[part 1 of 3: package /STELLANTIS/EPT/ASWCs]
AUTOSAR XML (schema 4-2-2)
package /STELLANTIS/EPT/ASWCs
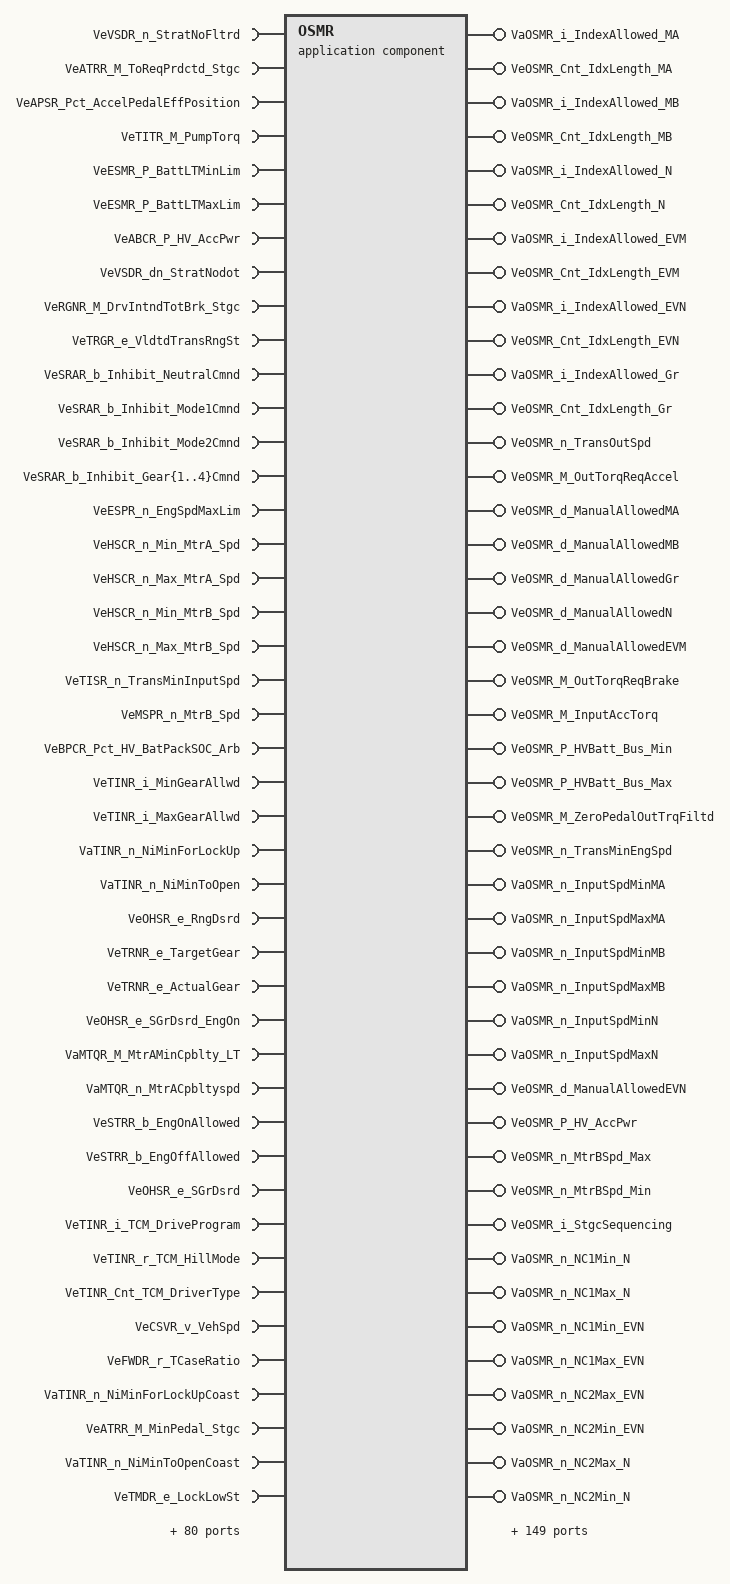
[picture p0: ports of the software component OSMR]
  application sw component type OSMR
    127 x require port:
      VeVSDR_n_StratNoFltrd: nonqueued-receiver-com-spec{data-element=Value, init-value=0}, required-interface=VeVSDR_n_StratNoFltrd
      VeATRR_M_ToReqPrdctd_Stgc: nonqueued-receiver-com-spec{data-element=Value, init-value=0}, required-interface=VeATRR_M_ToReqPrdctd_Stgc
      VeAPSR_Pct_AccelPedalEffPosition: nonqueued-receiver-com-spec{data-element=Value, init-value=0}, required-interface=VeAPSR_Pct_AccelPedalEffPosition
      VeTITR_M_PumpTorq: nonqueued-receiver-com-spec{data-element=Value, init-value=0}, required-interface=VeTITR_M_PumpTorq
      VeESMR_P_BattLTMinLim: nonqueued-receiver-com-spec{data-element=Value, init-value=0}, required-interface=VeESMR_P_BattLTMinLim
      VeESMR_P_BattLTMaxLim: nonqueued-receiver-com-spec{data-element=Value, init-value=0}, required-interface=VeESMR_P_BattLTMaxLim
      VeABCR_P_HV_AccPwr: nonqueued-receiver-com-spec{data-element=Value, init-value=0}, required-interface=VeABCR_P_HV_AccPwr
      VeVSDR_dn_StratNodot: nonqueued-receiver-com-spec{data-element=Value, init-value=0}, required-interface=VeVSDR_dn_StratNodot
      VeRGNR_M_DrvIntndTotBrk_Stgc: nonqueued-receiver-com-spec{data-element=Value, init-value=0}, required-interface=VeRGNR_M_DrvIntndTotBrk_Stgc
      VeTRGR_e_VldtdTransRngSt: nonqueued-receiver-com-spec{data-element=Value, init-value=CeTRGR_e_NoSelectionAvailable}, required-interface=VeTRGR_e_VldtdTransRngSt
      VeSRAR_b_Inhibit_NeutralCmnd: nonqueued-receiver-com-spec{data-element=Value, init-value=0}, required-interface=VeSRAR_b_Inhibit_NeutralCmnd
      VeSRAR_b_Inhibit_Mode1Cmnd: nonqueued-receiver-com-spec{data-element=Value, init-value=0}, required-interface=VeSRAR_b_Inhibit_Mode1Cmnd
      VeSRAR_b_Inhibit_Mode2Cmnd: nonqueued-receiver-com-spec{data-element=Value, init-value=0}, required-interface=VeSRAR_b_Inhibit_Mode2Cmnd
      VeSRAR_b_Inhibit_Gear{1..4}Cmnd: nonqueued-receiver-com-spec{data-element=Value, init-value=0}, required-interface=VeSRAR_b_Inhibit_Gear{1..4}Cmnd
      VeESPR_n_EngSpdMaxLim: nonqueued-receiver-com-spec{data-element=Value, init-value=0}, required-interface=VeESPR_n_EngSpdMaxLim
      VeHSCR_n_Min_MtrA_Spd: nonqueued-receiver-com-spec{data-element=Value, init-value=0}, required-interface=VeHSCR_n_Min_MtrA_Spd
      VeHSCR_n_Max_MtrA_Spd: nonqueued-receiver-com-spec{data-element=Value, init-value=0}, required-interface=VeHSCR_n_Max_MtrA_Spd
      VeHSCR_n_Min_MtrB_Spd: nonqueued-receiver-com-spec{data-element=Value, init-value=0}, required-interface=VeHSCR_n_Min_MtrB_Spd
      VeHSCR_n_Max_MtrB_Spd: nonqueued-receiver-com-spec{data-element=Value, init-value=0}, required-interface=VeHSCR_n_Max_MtrB_Spd
      VeTISR_n_TransMinInputSpd: nonqueued-receiver-com-spec{data-element=Value, init-value=0}, required-interface=VeTISR_n_TransMinInputSpd
      VeMSPR_n_MtrB_Spd: variation-point={short-label=vpVeMSPR_n_MtrB_Spd, sw-syscond=1}, nonqueued-receiver-com-spec{data-element=Value, init-value=0}, required-interface=VeMSPR_n_MtrB_Spd
      VeBPCR_Pct_HV_BatPackSOC_Arb: nonqueued-receiver-com-spec{data-element=Value, init-value=0}, required-interface=VeBPCR_Pct_HV_BatPackSOC_Arb
      VeTINR_i_MinGearAllwd: nonqueued-receiver-com-spec{data-element=Value, init-value=0}, required-interface=VeTINR_i_MinGearAllwd
      VeTINR_i_MaxGearAllwd: nonqueued-receiver-com-spec{data-element=Value, init-value=0}, required-interface=VeTINR_i_MaxGearAllwd
      VaTINR_n_NiMinForLockUp: nonqueued-receiver-com-spec{data-element=Value, init-value=9 x 0}, required-interface=VaTINR_n_NiMinForLockUp
      VaTINR_n_NiMinToOpen: nonqueued-receiver-com-spec{data-element=Value, init-value=9 x 0}, required-interface=VaTINR_n_NiMinToOpen
      VeOHSR_e_RngDsrd: nonqueued-receiver-com-spec{data-element=Value, init-value=CeOHSR_e_RngSel_N}, required-interface=VeOHSR_e_RngDsrd
      VeTRNR_e_TargetGear: nonqueued-receiver-com-spec{data-element=Value, init-value=CeTRNR_e_Neutral}, required-interface=VeTRNR_e_TargetGear
      VeTRNR_e_ActualGear: nonqueued-receiver-com-spec{data-element=Value, init-value=CeTRNR_e_Neutral}, required-interface=VeTRNR_e_ActualGear
      VeOHSR_e_SGrDsrd_EngOn: nonqueued-receiver-com-spec{data-element=Value, init-value=CeOHSR_e_SG_Reverse}, required-interface=VeOHSR_e_SGrDsrd_EngOn
      VaMTQR_M_MtrAMinCpblty_LT: nonqueued-receiver-com-spec{data-element=Value, init-value=16 x 0}, required-interface=VaMTQR_M_MtrAMinCpblty_LT
      VaMTQR_n_MtrACpbltyspd: nonqueued-receiver-com-spec{data-element=Value, init-value=16 x 0}, required-interface=VaMTQR_n_MtrACpbltyspd
      VeSTRR_b_EngOnAllowed: nonqueued-receiver-com-spec{data-element=Value, init-value=0}, required-interface=VeSTRR_b_EngOnAllowed
      VeSTRR_b_EngOffAllowed: nonqueued-receiver-com-spec{data-element=Value, init-value=0}, required-interface=VeSTRR_b_EngOffAllowed
      VeOHSR_e_SGrDsrd: nonqueued-receiver-com-spec{data-element=Value, init-value=CeOHSR_e_SG_Reverse}, required-interface=VeOHSR_e_SGrDsrd
      VeTINR_i_TCM_DriveProgram: nonqueued-receiver-com-spec{data-element=Value, init-value=0}, required-interface=VeTINR_i_TCM_DriveProgram
      VeTINR_r_TCM_HillMode: nonqueued-receiver-com-spec{data-element=Value, init-value=0}, required-interface=VeTINR_r_TCM_HillMode
      VeTINR_Cnt_TCM_DriverType: nonqueued-receiver-com-spec{data-element=Value, init-value=0}, required-interface=VeTINR_Cnt_TCM_DriverType
      VeCSVR_v_VehSpd: nonqueued-receiver-com-spec{data-element=Value, init-value=0}, required-interface=VeCSVR_v_VehSpd
      VeFWDR_r_TCaseRatio: nonqueued-receiver-com-spec{data-element=Value, init-value=0}, required-interface=VeFWDR_r_TCaseRatio
      VaTINR_n_NiMinForLockUpCoast: nonqueued-receiver-com-spec{data-element=Value, init-value=9 x 0}, required-interface=VaTINR_n_NiMinForLockUpCoast
      VeATRR_M_MinPedal_Stgc: nonqueued-receiver-com-spec{data-element=Value, init-value=0}, required-interface=VeATRR_M_MinPedal_Stgc
      VaTINR_n_NiMinToOpenCoast: nonqueued-receiver-com-spec{data-element=Value, init-value=9 x 0}, required-interface=VaTINR_n_NiMinToOpenCoast
      VeTMDR_e_LockLowSt: nonqueued-receiver-com-spec{data-element=Value, init-value=CeTMDR_e_Off}, required-interface=VeTMDR_e_LockLowSt
      VeCSVR_l_WhlRadius: nonqueued-receiver-com-spec{data-element=Value, init-value=0}, required-interface=VeCSVR_l_WhlRadius
      VeCTCR_b_MinCreep_Enable: nonqueued-receiver-com-spec{data-element=Value, init-value=0}, required-interface=VeCTCR_b_MinCreep_Enable
      VeTRGR_b_ManualMode: nonqueued-receiver-com-spec{data-element=Value, init-value=0}, required-interface=VeTRGR_b_ManualMode
      VeEOCR_r_ColdCtrlCostFact_Stgc: nonqueued-receiver-com-spec{data-element=Value, init-value=0}, required-interface=VeEOCR_r_ColdCtrlCostFact_Stgc
      VeFWDR_e_Tcase_Stat: nonqueued-receiver-com-spec{data-element=Value, init-value=CeFWDR_e_ShiftINProg}, required-interface=VeFWDR_e_Tcase_Stat
      VeTMDR_i_TrueTrrnMd: nonqueued-receiver-com-spec{data-element=Value, init-value=0}, required-interface=VeTMDR_i_TrueTrrnMd
      VeHSER_e_HRSR_State: variation-point={short-label=vpVeHSER_e_HRSR_State, sw-syscond=1}, nonqueued-receiver-com-spec{data-element=Value, init-value=CeHSER_e_Neut_State}, required-interface=VeHSER_e_HRSR_State
      VeTRNR_e_TCM_ActiveHybridGear: nonqueued-receiver-com-spec{data-element=Value, init-value=CeTRNR_e_Neutral}, required-interface=VeTRNR_e_TCM_ActiveHybridGear
      VeTRNR_e_TCM_ActiveXNGear: nonqueued-receiver-com-spec{data-element=Value, init-value=CeTRNR_e_Neutral}, required-interface=VeTRNR_e_TCM_ActiveXNGear
      VeTRNR_e_TCM_ActiveEVGear: nonqueued-receiver-com-spec{data-element=Value, init-value=CeTRNR_e_Neutral}, required-interface=VeTRNR_e_TCM_ActiveEVGear
      VeFWDR_r_Axle_Ratio: nonqueued-receiver-com-spec{data-element=Value, init-value=0}, required-interface=VeFWDR_r_Axle_Ratio
      VaETQR_M_EngCapabilityMax: nonqueued-receiver-com-spec{data-element=Value, init-value=16 x 0}, required-interface=VaETQR_M_EngCapabilityMax
      VaETQR_n_EngCapability: nonqueued-receiver-com-spec{data-element=Value, init-value=16 x 0}, required-interface=VaETQR_n_EngCapability
      VeTINR_t_TCM_TimeToSpeedChange: nonqueued-receiver-com-spec{data-element=Value, init-value=0}, required-interface=VeTINR_t_TCM_TimeToSpeedChange
      VeHSCR_n_Min_MtrC_Spd: nonqueued-receiver-com-spec{data-element=Value, init-value=0}, required-interface=VeHSCR_n_Min_MtrC_Spd
      VeHSCR_n_Max_MtrC_Spd: nonqueued-receiver-com-spec{data-element=Value, init-value=0}, required-interface=VeHSCR_n_Max_MtrC_Spd
      VeADCR_e_WEDCmndArb: variation-point={short-label=vpVeADCR_e_WEDCmndArb, sw-syscond=1}, nonqueued-receiver-com-spec{data-element=Value, init-value=CeADCR_e_ReqOpt}, required-interface=VeADCR_e_WEDCmndArb
      VeINVR_e_MtrA_InvrtrSt: nonqueued-receiver-com-spec{data-element=Value, init-value=CeINVR_e_NormalPowerStageOff}, required-interface=VeINVR_e_MtrA_InvrtrSt
      VeBPCR_e_HV_BatCntctrStat: nonqueued-receiver-com-spec{data-element=Value, init-value=CeHVTR_e_Open}, required-interface=VeBPCR_e_HV_BatCntctrStat
      VeENGR_b_PnLimitActvFlg: nonqueued-receiver-com-spec{data-element=Value, init-value=0}, required-interface=VeENGR_b_PnLimitActvFlg
      VeESMR_P_BoostCnvrtr_LT_ChrgPwrLmt: nonqueued-receiver-com-spec{data-element=Value, init-value=0}, required-interface=VeESMR_P_BoostCnvrtr_LT_ChrgPwrLmt
      VeESMR_P_BoostCnvrtr_LT_DschrgPwrLmt: nonqueued-receiver-com-spec{data-element=Value, init-value=0}, required-interface=VeESMR_P_BoostCnvrtr_LT_DschrgPwrLmt
      VeTIMR_e_RaceOptions_Sts: nonqueued-receiver-com-spec{data-element=Value, init-value=CeTIMR_e_NoOptionSelected}, required-interface=VeTIMR_e_RaceOptions_Sts
      VeDMDR_i_DrvMdArbIdx: nonqueued-receiver-com-spec{data-element=Value, init-value=0}, required-interface=VeDMDR_i_DrvMdArbIdx
      VaMTQR_n_MtrBCpbltyspd: nonqueued-receiver-com-spec{data-element=Value, init-value=16 x 0}, required-interface=VaMTQR_n_MtrBCpbltyspd
      VaMTQR_n_MtrCCpbltyspd: nonqueued-receiver-com-spec{data-element=Value, init-value=16 x 0}, required-interface=VaMTQR_n_MtrCCpbltyspd
      VaMTQR_M_MtrAMaxCpblty_LT: nonqueued-receiver-com-spec{data-element=Value, init-value=16 x 0}, required-interface=VaMTQR_M_MtrAMaxCpblty_LT
      VaMTQR_M_MtrBMaxCpblty_LT: nonqueued-receiver-com-spec{data-element=Value, init-value=16 x 0}, required-interface=VaMTQR_M_MtrBMaxCpblty_LT
      VaMTQR_M_MtrCMaxCpblty_LT: nonqueued-receiver-com-spec{data-element=Value, init-value=16 x 0}, required-interface=VaMTQR_M_MtrCMaxCpblty_LT
      VeADCR_i_WEDCmndArbPrioLvl: variation-point={short-label=vpVeADCR_i_WEDCmndArbPrioLvl, sw-syscond=1}, nonqueued-receiver-com-spec{data-element=Value, init-value=0}, required-interface=VeADCR_i_WEDCmndArbPrioLvl
      VeEBMR_e_eBoostStatus: variation-point={short-label=vpVeEBMR_e_eBoostStatus, sw-syscond=1}, nonqueued-receiver-com-spec{data-element=Value, init-value=CeEBMR_e_eBoostOFF}, required-interface=VeEBMR_e_eBoostStatus
      VeENGR_b_OilDil_EngMinPwrEnbl: nonqueued-receiver-com-spec{data-element=Value, init-value=0}, required-interface=VeENGR_b_OilDil_EngMinPwrEnbl
      VaETQR_M_EngCapabilityMinOff: nonqueued-receiver-com-spec{data-element=Value, init-value=16 x 0}, required-interface=VaETQR_M_EngCapabilityMinOff
      VeSRAR_b_limitInputTrq: nonqueued-receiver-com-spec{data-element=Value, init-value=0}, required-interface=VeSRAR_b_limitInputTrq
      VeSTRR_e_HybStrtrSt: nonqueued-receiver-com-spec{data-element=Value, init-value=CeSTRR_e_KeyOffSt}, required-interface=VeSTRR_e_HybStrtrSt
      VeOHSR_b_EngDsrd: nonqueued-receiver-com-spec{data-element=Value, init-value=0}, required-interface=VeOHSR_b_EngDsrd
      VeWTAR_M_FrntAxlMaxRq: nonqueued-receiver-com-spec{data-element=Value, init-value=0}, required-interface=VeWTAR_M_FrntAxlMaxRq
      VeWTAR_M_FrntAxlMinRq: nonqueued-receiver-com-spec{data-element=Value, init-value=0}, required-interface=VeWTAR_M_FrntAxlMinRq
      VeWTAR_M_RrAxlMaxRq: nonqueued-receiver-com-spec{data-element=Value, init-value=0}, required-interface=VeWTAR_M_RrAxlMaxRq
      VeWTAR_M_RrAxlMinRq: nonqueued-receiver-com-spec{data-element=Value, init-value=0}, required-interface=VeWTAR_M_RrAxlMinRq
      VeWTAR_r_PRNDL_Coeff: nonqueued-receiver-com-spec{data-element=Value, init-value=0}, required-interface=VeWTAR_r_PRNDL_Coeff
      VaOMNR_M_PrevToFOpt_N: variation-point={short-label=vpVaOMNR_M_PrevToFOpt_N, sw-syscond=1}, nonqueued-receiver-com-spec{data-element=Value, init-value=9 x 0}, required-interface=VaOMNR_M_PrevToFOpt_N
      VaOMAR_M_PrevToFOpt_MA: nonqueued-receiver-com-spec{data-element=Value, init-value=9 x 0}, required-interface=VaOMAR_M_PrevToFOpt_MA
      VaOMBR_M_PrevToFOpt_MB: nonqueued-receiver-com-spec{data-element=Value, init-value=9 x 0}, required-interface=VaOMBR_M_PrevToFOpt_MB
      VaOGRR_M_PrevToFOpt_GB: nonqueued-receiver-com-spec{data-element=Value, init-value=9 x 0}, required-interface=VaOGRR_M_PrevToFOpt_GB
      VaOEVR_M_PrevToFOpt_EVM: nonqueued-receiver-com-spec{data-element=Value, init-value=9 x 0}, required-interface=VaOEVR_M_PrevToFOpt_EVM
      VaOEVR_M_PrevToFOpt_EVN: nonqueued-receiver-com-spec{data-element=Value, init-value=9 x 0}, required-interface=VaOEVR_M_PrevToFOpt_EVN
      VaOMNR_M_PrevToROpt_N: variation-point={short-label=vpVaOMNR_M_PrevToROpt_N, sw-syscond=1}, nonqueued-receiver-com-spec{data-element=Value, init-value=9 x 0}, required-interface=VaOMNR_M_PrevToROpt_N
      VaOMAR_M_PrevToROpt_MA: nonqueued-receiver-com-spec{data-element=Value, init-value=9 x 0}, required-interface=VaOMAR_M_PrevToROpt_MA
      VaOMBR_M_PrevToROpt_MB: nonqueued-receiver-com-spec{data-element=Value, init-value=9 x 0}, required-interface=VaOMBR_M_PrevToROpt_MB
      VaOGRR_M_PrevToROpt_GB: nonqueued-receiver-com-spec{data-element=Value, init-value=9 x 0}, required-interface=VaOGRR_M_PrevToROpt_GB
      VaOEVR_M_PrevToROpt_EVM: nonqueued-receiver-com-spec{data-element=Value, init-value=9 x 0}, required-interface=VaOEVR_M_PrevToROpt_EVM
      VaOEVR_M_PrevToROpt_EVN: nonqueued-receiver-com-spec{data-element=Value, init-value=9 x 0}, required-interface=VaOEVR_M_PrevToROpt_EVN
      VeBACR_r_CostFactSOCNeg_Stgc: nonqueued-receiver-com-spec{data-element=Value, init-value=0}, required-interface=VeBACR_r_CostFactSOCNeg_Stgc
      VeBACR_r_CostFactSOCPos_Stgc: nonqueued-receiver-com-spec{data-element=Value, init-value=0}, required-interface=VeBACR_r_CostFactSOCPos_Stgc
      VeBACR_P_BattPwrShift_Stgc: nonqueued-receiver-com-spec{data-element=Value, init-value=0}, required-interface=VeBACR_P_BattPwrShift_Stgc
      VeEOCR_n_Ni_ColdCtrl: nonqueued-receiver-com-spec{data-element=Value, init-value=0}, required-interface=VeEOCR_n_Ni_ColdCtrl
      VeEOCR_M_Ti_ColdCtrl_Stgc: nonqueued-receiver-com-spec{data-element=Value, init-value=0}, required-interface=VeEOCR_M_Ti_ColdCtrl_Stgc
      VeBACR_P_BattPwrShift_ZeroPdl: nonqueued-receiver-com-spec{data-element=Value, init-value=0}, required-interface=VeBACR_P_BattPwrShift_ZeroPdl
      VeSCCR_b_PerfAWDFlag: variation-point={short-label=vpVeSCCR_b_PerfAWDFlag, sw-syscond=1}, nonqueued-receiver-com-spec{data-element=Value, init-value=0}, required-interface=VeSCCR_b_PerfAWDFlag
      VeSCCR_M_FrntAxlAdhMax: nonqueued-receiver-com-spec{data-element=Value, init-value=0}, required-interface=VeSCCR_M_FrntAxlAdhMax
      VeSCCR_M_FrntAxlAdhMin: nonqueued-receiver-com-spec{data-element=Value, init-value=0}, required-interface=VeSCCR_M_FrntAxlAdhMin
      VeSCCR_M_RrAxlAdhMax: nonqueued-receiver-com-spec{data-element=Value, init-value=0}, required-interface=VeSCCR_M_RrAxlAdhMax
      VeSCCR_M_RrAxlAdhMin: nonqueued-receiver-com-spec{data-element=Value, init-value=0}, required-interface=VeSCCR_M_RrAxlAdhMin
      VeSCCR_M_FrntAxlStrtgcMax_OL: variation-point={short-label=vpVeSCCR_M_FrntAxlStrtgcMax_OL, sw-syscond=1}, nonqueued-receiver-com-spec{data-element=Value, init-value=0}, required-interface=VeSCCR_M_FrntAxlStrtgcMax_OL
      VeSCCR_M_FrntAxlStrtgcMin_OL: variation-point={short-label=vpVeSCCR_M_FrntAxlStrtgcMin_OL, sw-syscond=1}, nonqueued-receiver-com-spec{data-element=Value, init-value=0}, required-interface=VeSCCR_M_FrntAxlStrtgcMin_OL
      VeSCCR_M_RrAxlStrtgcMax_OL: variation-point={short-label=vpVeSCCR_M_RrAxlStrtgcMax_OL, sw-syscond=1}, nonqueued-receiver-com-spec{data-element=Value, init-value=0}, required-interface=VeSCCR_M_RrAxlStrtgcMax_OL
      VeSCCR_M_RrAxlStrtgcMin_OL: variation-point={short-label=vpVeSCCR_M_RrAxlStrtgcMin_OL, sw-syscond=1}, nonqueued-receiver-com-spec{data-element=Value, init-value=0}, required-interface=VeSCCR_M_RrAxlStrtgcMin_OL
      VeADCR_P_PwrRsrv4EngmtRaw: nonqueued-receiver-com-spec{data-element=Value, init-value=0}, required-interface=VeADCR_P_PwrRsrv4EngmtRaw
      VeBCPR_M_BeltCapMaxPrll: nonqueued-receiver-com-spec{data-element=Value, init-value=0}, required-interface=VeBCPR_M_BeltCapMaxPrll
      VeBCPR_M_BeltCapMinPrll: nonqueued-receiver-com-spec{data-element=Value, init-value=0}, required-interface=VeBCPR_M_BeltCapMinPrll
      VeBCPR_M_BeltCapMaxSer_Eff: nonqueued-receiver-com-spec{data-element=Value, init-value=0}, required-interface=VeBCPR_M_BeltCapMaxSer_Eff
      VeBCPR_M_BeltCapMinSer_Eff: nonqueued-receiver-com-spec{data-element=Value, init-value=0}, required-interface=VeBCPR_M_BeltCapMinSer_Eff
      VeINVR_T_MtrA_Temp: nonqueued-receiver-com-spec{data-element=Value, init-value=0}, required-interface=VeINVR_T_MtrA_Temp
      VeINVR_T_MtrA_InvrtrTemp: nonqueued-receiver-com-spec{data-element=Value, init-value=0}, required-interface=VeINVR_T_MtrA_InvrtrTemp
      VeINVR_T_MtrB_Temp: nonqueued-receiver-com-spec{data-element=Value, init-value=0}, required-interface=VeINVR_T_MtrB_Temp
      VeINVR_T_MtrB_InvrtrTemp: nonqueued-receiver-com-spec{data-element=Value, init-value=0}, required-interface=VeINVR_T_MtrB_InvrtrTemp
      VeINVR_T_MtrC_Temp: nonqueued-receiver-com-spec{data-element=Value, init-value=0}, required-interface=VeINVR_T_MtrC_Temp
      VeINVR_T_MtrC_InvrtrTemp: nonqueued-receiver-com-spec{data-element=Value, init-value=0}, required-interface=VeINVR_T_MtrC_InvrtrTemp
      VeBPCR_T_BatModTmp: nonqueued-receiver-com-spec{data-element=Value, init-value=0}, required-interface=VeBPCR_T_BatModTmp
    193 x provide port:
      VaOSMR_i_IndexAllowed_MA: nonqueued-sender-com-spec{data-element=Value, init-value=9 x 0}, provided-interface=VaOSMR_i_IndexAllowed_MA
      VeOSMR_Cnt_IdxLength_MA: nonqueued-sender-com-spec{data-element=Value, init-value=0}, provided-interface=VeOSMR_Cnt_IdxLength_MA
      VaOSMR_i_IndexAllowed_MB: nonqueued-sender-com-spec{data-element=Value, init-value=9 x 0}, provided-interface=VaOSMR_i_IndexAllowed_MB
      VeOSMR_Cnt_IdxLength_MB: nonqueued-sender-com-spec{data-element=Value, init-value=0}, provided-interface=VeOSMR_Cnt_IdxLength_MB
      VaOSMR_i_IndexAllowed_N: nonqueued-sender-com-spec{data-element=Value, init-value=9 x 0}, provided-interface=VaOSMR_i_IndexAllowed_N
      VeOSMR_Cnt_IdxLength_N: nonqueued-sender-com-spec{data-element=Value, init-value=0}, provided-interface=VeOSMR_Cnt_IdxLength_N
      VaOSMR_i_IndexAllowed_EVM: nonqueued-sender-com-spec{data-element=Value, init-value=9 x 0}, provided-interface=VaOSMR_i_IndexAllowed_EVM
      VeOSMR_Cnt_IdxLength_EVM: nonqueued-sender-com-spec{data-element=Value, init-value=0}, provided-interface=VeOSMR_Cnt_IdxLength_EVM
      VaOSMR_i_IndexAllowed_EVN: nonqueued-sender-com-spec{data-element=Value, init-value=9 x 0}, provided-interface=VaOSMR_i_IndexAllowed_EVN
      VeOSMR_Cnt_IdxLength_EVN: nonqueued-sender-com-spec{data-element=Value, init-value=0}, provided-interface=VeOSMR_Cnt_IdxLength_EVN
      VaOSMR_i_IndexAllowed_Gr: nonqueued-sender-com-spec{data-element=Value, init-value=9 x 0}, provided-interface=VaOSMR_i_IndexAllowed_Gr
      VeOSMR_Cnt_IdxLength_Gr: nonqueued-sender-com-spec{data-element=Value, init-value=0}, provided-interface=VeOSMR_Cnt_IdxLength_Gr
      VeOSMR_n_TransOutSpd: nonqueued-sender-com-spec{data-element=Value, init-value=0}, provided-interface=VeOSMR_n_TransOutSpd
      VeOSMR_M_OutTorqReqAccel: nonqueued-sender-com-spec{data-element=Value, init-value=0}, provided-interface=VeOSMR_M_OutTorqReqAccel
      VeOSMR_d_ManualAllowedMA: nonqueued-sender-com-spec{data-element=Value, init-value=0}, provided-interface=VeOSMR_d_ManualAllowedMA
      VeOSMR_d_ManualAllowedMB: nonqueued-sender-com-spec{data-element=Value, init-value=0}, provided-interface=VeOSMR_d_ManualAllowedMB
      VeOSMR_d_ManualAllowedGr: nonqueued-sender-com-spec{data-element=Value, init-value=0}, provided-interface=VeOSMR_d_ManualAllowedGr
      VeOSMR_d_ManualAllowedN: nonqueued-sender-com-spec{data-element=Value, init-value=0}, provided-interface=VeOSMR_d_ManualAllowedN
      VeOSMR_d_ManualAllowedEVM: nonqueued-sender-com-spec{data-element=Value, init-value=0}, provided-interface=VeOSMR_d_ManualAllowedEVM
      VeOSMR_M_OutTorqReqBrake: nonqueued-sender-com-spec{data-element=Value, init-value=0}, provided-interface=VeOSMR_M_OutTorqReqBrake
      VeOSMR_M_InputAccTorq: nonqueued-sender-com-spec{data-element=Value, init-value=0}, provided-interface=VeOSMR_M_InputAccTorq
      VeOSMR_P_HVBatt_Bus_Min: nonqueued-sender-com-spec{data-element=Value, init-value=0}, provided-interface=VeOSMR_P_HVBatt_Bus_Min
      VeOSMR_P_HVBatt_Bus_Max: nonqueued-sender-com-spec{data-element=Value, init-value=0}, provided-interface=VeOSMR_P_HVBatt_Bus_Max
      VeOSMR_M_ZeroPedalOutTrqFiltd: nonqueued-sender-com-spec{data-element=Value, init-value=0}, provided-interface=VeOSMR_M_ZeroPedalOutTrqFiltd
      VeOSMR_n_TransMinEngSpd: nonqueued-sender-com-spec{data-element=Value, init-value=0}, provided-interface=VeOSMR_n_TransMinEngSpd
      VaOSMR_n_InputSpdMinMA: nonqueued-sender-com-spec{data-element=Value, init-value=9 x 0}, provided-interface=VaOSMR_n_InputSpdMinMA
      VaOSMR_n_InputSpdMaxMA: nonqueued-sender-com-spec{data-element=Value, init-value=9 x 0}, provided-interface=VaOSMR_n_InputSpdMaxMA
      VaOSMR_n_InputSpdMinMB: nonqueued-sender-com-spec{data-element=Value, init-value=9 x 0}, provided-interface=VaOSMR_n_InputSpdMinMB
      VaOSMR_n_InputSpdMaxMB: nonqueued-sender-com-spec{data-element=Value, init-value=9 x 0}, provided-interface=VaOSMR_n_InputSpdMaxMB
      VaOSMR_n_InputSpdMinN: nonqueued-sender-com-spec{data-element=Value, init-value=9 x 0}, provided-interface=VaOSMR_n_InputSpdMinN
      VaOSMR_n_InputSpdMaxN: nonqueued-sender-com-spec{data-element=Value, init-value=9 x 0}, provided-interface=VaOSMR_n_InputSpdMaxN
      VeOSMR_d_ManualAllowedEVN: nonqueued-sender-com-spec{data-element=Value, init-value=0}, provided-interface=VeOSMR_d_ManualAllowedEVN
      VeOSMR_P_HV_AccPwr: nonqueued-sender-com-spec{data-element=Value, init-value=0}, provided-interface=VeOSMR_P_HV_AccPwr
      VeOSMR_n_MtrBSpd_Max: nonqueued-sender-com-spec{data-element=Value, init-value=0}, provided-interface=VeOSMR_n_MtrBSpd_Max
      VeOSMR_n_MtrBSpd_Min: nonqueued-sender-com-spec{data-element=Value, init-value=0}, provided-interface=VeOSMR_n_MtrBSpd_Min
      VeOSMR_i_StgcSequencing: nonqueued-sender-com-spec{data-element=Value, init-value=0}, provided-interface=VeOSMR_i_StgcSequencing
      VaOSMR_n_NC1Min_N: nonqueued-sender-com-spec{data-element=Value, init-value=9 x 0}, provided-interface=VaOSMR_n_NC1Min_N
      VaOSMR_n_NC1Max_N: nonqueued-sender-com-spec{data-element=Value, init-value=9 x 0}, provided-interface=VaOSMR_n_NC1Max_N
      VaOSMR_n_NC1Min_EVN: nonqueued-sender-com-spec{data-element=Value, init-value=9 x 0}, provided-interface=VaOSMR_n_NC1Min_EVN
      VaOSMR_n_NC1Max_EVN: nonqueued-sender-com-spec{data-element=Value, init-value=9 x 0}, provided-interface=VaOSMR_n_NC1Max_EVN
      VaOSMR_n_NC2Max_EVN: nonqueued-sender-com-spec{data-element=Value, init-value=9 x 0}, provided-interface=VaOSMR_n_NC2Max_EVN
      VaOSMR_n_NC2Min_EVN: nonqueued-sender-com-spec{data-element=Value, init-value=9 x 0}, provided-interface=VaOSMR_n_NC2Min_EVN
      VaOSMR_n_NC2Max_N: nonqueued-sender-com-spec{data-element=Value, init-value=9 x 0}, provided-interface=VaOSMR_n_NC2Max_N
      VaOSMR_n_NC2Min_N: nonqueued-sender-com-spec{data-element=Value, init-value=9 x 0}, provided-interface=VaOSMR_n_NC2Min_N
      VeOSMR_e_ActualGear: nonqueued-sender-com-spec{data-element=Value, init-value=CeTRNR_e_Neutral}, provided-interface=VeOSMR_e_ActualGear
      VeOSMR_e_TargetGear: nonqueued-sender-com-spec{data-element=Value, init-value=CeTRNR_e_Neutral}, provided-interface=VeOSMR_e_TargetGear
      VaOSMR_n_NTurb_FromNo: nonqueued-sender-com-spec{data-element=Value, init-value=9 x 0}, provided-interface=VaOSMR_n_NTurb_FromNo
      VaOSMR_n_NtiMax_MA: nonqueued-sender-com-spec{data-element=Value, init-value=9 x 0}, provided-interface=VaOSMR_n_NtiMax_MA
      VaOSMR_n_NtiMin_MA: nonqueued-sender-com-spec{data-element=Value, init-value=9 x 0}, provided-interface=VaOSMR_n_NtiMin_MA
      VaOSMR_n_NtiMax_MB: nonqueued-sender-com-spec{data-element=Value, init-value=9 x 0}, provided-interface=VaOSMR_n_NtiMax_MB
      VaOSMR_n_NtiMin_MB: nonqueued-sender-com-spec{data-element=Value, init-value=9 x 0}, provided-interface=VaOSMR_n_NtiMin_MB
      VaOSMR_n_NtiMax_N: nonqueued-sender-com-spec{data-element=Value, init-value=9 x 0}, provided-interface=VaOSMR_n_NtiMax_N
      VaOSMR_n_NtiMin_N: nonqueued-sender-com-spec{data-element=Value, init-value=9 x 0}, provided-interface=VaOSMR_n_NtiMin_N
      VaOSMR_n_NtiMax_Gr: nonqueued-sender-com-spec{data-element=Value, init-value=9 x 0}, provided-interface=VaOSMR_n_NtiMax_Gr
      VaOSMR_n_NtiMin_Gr: nonqueued-sender-com-spec{data-element=Value, init-value=9 x 0}, provided-interface=VaOSMR_n_NtiMin_Gr
      VaOSMR_n_NtiMax_EVM: nonqueued-sender-com-spec{data-element=Value, init-value=9 x 0}, provided-interface=VaOSMR_n_NtiMax_EVM
      VaOSMR_n_NtiMin_EVM: nonqueued-sender-com-spec{data-element=Value, init-value=9 x 0}, provided-interface=VaOSMR_n_NtiMin_EVM
      VaOSMR_n_NtiMax_EVN: nonqueued-sender-com-spec{data-element=Value, init-value=9 x 0}, provided-interface=VaOSMR_n_NtiMax_EVN
      VaOSMR_n_NtiMin_EVN: nonqueued-sender-com-spec{data-element=Value, init-value=9 x 0}, provided-interface=VaOSMR_n_NtiMin_EVN
      VeOSMR_b_EnblGearSlctn: nonqueued-sender-com-spec{data-element=Value, init-value=0}, provided-interface=VeOSMR_b_EnblGearSlctn
      VeOSMR_M_OutTorqReqAccel_Raw: nonqueued-sender-com-spec{data-element=Value, init-value=0}, provided-interface=VeOSMR_M_OutTorqReqAccel_Raw
      VeOSMR_b_StgcInGSIMode: nonqueued-sender-com-spec{data-element=Value, init-value=0}, provided-interface=VeOSMR_b_StgcInGSIMode
      VeOSMR_d_StgcRngSts_AllowedN: nonqueued-sender-com-spec{data-element=Value, init-value=0}, provided-interface=VeOSMR_d_StgcRngSts_AllowedN
      VeOSMR_d_StgcRngSts_AllowedMA: nonqueued-sender-com-spec{data-element=Value, init-value=0}, provided-interface=VeOSMR_d_StgcRngSts_AllowedMA
      VeOSMR_d_StgcRngSts_AllowedMB: nonqueued-sender-com-spec{data-element=Value, init-value=0}, provided-interface=VeOSMR_d_StgcRngSts_AllowedMB
      VeOSMR_d_StgcRngSts_AllowedGr: nonqueued-sender-com-spec{data-element=Value, init-value=0}, provided-interface=VeOSMR_d_StgcRngSts_AllowedGr
      VeOSMR_d_StgcRngSts_AllowedEVM: nonqueued-sender-com-spec{data-element=Value, init-value=0}, provided-interface=VeOSMR_d_StgcRngSts_AllowedEVM
      VeOSMR_d_StgcRngSts_AllowedEVN: nonqueued-sender-com-spec{data-element=Value, init-value=0}, provided-interface=VeOSMR_d_StgcRngSts_AllowedEVN
      VeOSMR_b_SeriesModeAllowed: nonqueued-sender-com-spec{data-element=Value, init-value=0}, provided-interface=VeOSMR_b_SeriesModeAllowed
      VaOSMR_d_FinalAllwdOpt: nonqueued-sender-com-spec{data-element=Value, init-value=6 x 0}, provided-interface=VaOSMR_d_FinalAllwdOpt
      VaOSMR_d_FinalAllwdDsrd: nonqueued-sender-com-spec{data-element=Value, init-value=6 x 0}, provided-interface=VaOSMR_d_FinalAllwdDsrd
      VeOSMR_d_FxdGrRngSts_AllowedMA: nonqueued-sender-com-spec{data-element=Value, init-value=0}, provided-interface=VeOSMR_d_FxdGrRngSts_AllowedMA
      VeOSMR_d_FxdGrRngSts_AllowedMB: nonqueued-sender-com-spec{data-element=Value, init-value=0}, provided-interface=VeOSMR_d_FxdGrRngSts_AllowedMB
      VeOSMR_d_FxdGrRngSts_AllowedN: nonqueued-sender-com-spec{data-element=Value, init-value=0}, provided-interface=VeOSMR_d_FxdGrRngSts_AllowedN
      VeOSMR_d_FxdGrRngSts_AllowedGr: nonqueued-sender-com-spec{data-element=Value, init-value=0}, provided-interface=VeOSMR_d_FxdGrRngSts_AllowedGr
      VeOSMR_d_FxdGrRngSts_AllowedEVM: nonqueued-sender-com-spec{data-element=Value, init-value=0}, provided-interface=VeOSMR_d_FxdGrRngSts_AllowedEVM
      VeOSMR_d_FxdGrRngSts_AllowedEVN: nonqueued-sender-com-spec{data-element=Value, init-value=0}, provided-interface=VeOSMR_d_FxdGrRngSts_AllowedEVN
      VaOSMR_d_FinalAllwdFxdGr: nonqueued-sender-com-spec{data-element=Value, init-value=6 x 0}, provided-interface=VaOSMR_d_FinalAllwdFxdGr
      VeOSMR_e_TargetGear_GSI: nonqueued-sender-com-spec{data-element=Value, init-value=CeTRNR_e_Neutral}, provided-interface=VeOSMR_e_TargetGear_GSI
      VeOSMR_n_InputSpdMinMAAct: nonqueued-sender-com-spec{data-element=Value, init-value=0}, provided-interface=VeOSMR_n_InputSpdMinMAAct
      VeOSMR_n_InputSpdMaxMAAct: nonqueued-sender-com-spec{data-element=Value, init-value=0}, provided-interface=VeOSMR_n_InputSpdMaxMAAct
      VeOSMR_n_InputSpdMinMATgt: nonqueued-sender-com-spec{data-element=Value, init-value=0}, provided-interface=VeOSMR_n_InputSpdMinMATgt
      VeOSMR_n_InputSpdMaxMATgt: nonqueued-sender-com-spec{data-element=Value, init-value=0}, provided-interface=VeOSMR_n_InputSpdMaxMATgt
      VeOSMR_n_InputSpdMinMBAct: nonqueued-sender-com-spec{data-element=Value, init-value=0}, provided-interface=VeOSMR_n_InputSpdMinMBAct
      VeOSMR_n_InputSpdMaxMBAct: nonqueued-sender-com-spec{data-element=Value, init-value=0}, provided-interface=VeOSMR_n_InputSpdMaxMBAct
      VeOSMR_n_InputSpdMinMBTgt: nonqueued-sender-com-spec{data-element=Value, init-value=0}, provided-interface=VeOSMR_n_InputSpdMinMBTgt
      VeOSMR_n_InputSpdMaxMBTgt: nonqueued-sender-com-spec{data-element=Value, init-value=0}, provided-interface=VeOSMR_n_InputSpdMaxMBTgt
      VeOSMR_n_InputSpdMinNAct: nonqueued-sender-com-spec{data-element=Value, init-value=0}, provided-interface=VeOSMR_n_InputSpdMinNAct
      VeOSMR_n_InputSpdMaxNAct: nonqueued-sender-com-spec{data-element=Value, init-value=0}, provided-interface=VeOSMR_n_InputSpdMaxNAct
      VeOSMR_n_InputSpdMinNTgt: nonqueued-sender-com-spec{data-element=Value, init-value=0}, provided-interface=VeOSMR_n_InputSpdMinNTgt
      VeOSMR_n_InputSpdMaxNTgt: nonqueued-sender-com-spec{data-element=Value, init-value=0}, provided-interface=VeOSMR_n_InputSpdMaxNTgt
      VeOSMR_n_TransOutSpdRaw: nonqueued-sender-com-spec{data-element=Value, init-value=0}, provided-interface=VeOSMR_n_TransOutSpdRaw
      VeOSMR_d_SoftCheckAllwd_MA: nonqueued-sender-com-spec{data-element=Value, init-value=0}, provided-interface=VeOSMR_d_SoftCheckAllwd_MA
      VeOSMR_d_SoftCheckAllwd_MB: nonqueued-sender-com-spec{data-element=Value, init-value=0}, provided-interface=VeOSMR_d_SoftCheckAllwd_MB
      VeOSMR_d_SoftCheckAllwd_N: nonqueued-sender-com-spec{data-element=Value, init-value=0}, provided-interface=VeOSMR_d_SoftCheckAllwd_N
      VeOSMR_d_SoftCheckAllwd_Gr: nonqueued-sender-com-spec{data-element=Value, init-value=0}, provided-interface=VeOSMR_d_SoftCheckAllwd_Gr
      VeOSMR_d_SoftCheckAllwd_EVM: nonqueued-sender-com-spec{data-element=Value, init-value=0}, provided-interface=VeOSMR_d_SoftCheckAllwd_EVM
      VeOSMR_d_SoftCheckAllwd_EVN: nonqueued-sender-com-spec{data-element=Value, init-value=0}, provided-interface=VeOSMR_d_SoftCheckAllwd_EVN
      VeOSMR_b_TempEVDrvMdInhibit: nonqueued-sender-com-spec{data-element=Value, init-value=0}, provided-interface=VeOSMR_b_TempEVDrvMdInhibit
      VeOSMR_i_Hybrid_ST2Idx: nonqueued-sender-com-spec{data-element=Value, init-value=0}, provided-interface=VeOSMR_i_Hybrid_ST2Idx
      VeOSMR_b_EngOffAllwdOpt: nonqueued-sender-com-spec{data-element=Value, init-value=0}, provided-interface=VeOSMR_b_EngOffAllwdOpt
      VeOSMR_n_NoMax_M1_WithWideMargin: nonqueued-sender-com-spec{data-element=Value, init-value=0}, provided-interface=VeOSMR_n_NoMax_M1_WithWideMargin
      VeOSMR_n_InputSpdMinM1_ToilDep: nonqueued-sender-com-spec{data-element=Value, init-value=0}, provided-interface=VeOSMR_n_InputSpdMinM1_ToilDep
      VeOSMR_n_InputSpdMaxM1_ToilDep: nonqueued-sender-com-spec{data-element=Value, init-value=0}, provided-interface=VeOSMR_n_InputSpdMaxM1_ToilDep
      VeOSMR_n_InputSpdMinM2_ToilDep: nonqueued-sender-com-spec{data-element=Value, init-value=0}, provided-interface=VeOSMR_n_InputSpdMinM2_ToilDep
      VeOSMR_n_InputSpdMaxM2_ToilDep: nonqueued-sender-com-spec{data-element=Value, init-value=0}, provided-interface=VeOSMR_n_InputSpdMaxM2_ToilDep
      VeOSMR_n_InputSpdMinM1: nonqueued-sender-com-spec{data-element=Value, init-value=0}, provided-interface=VeOSMR_n_InputSpdMinM1
      VeOSMR_n_InputSpdMaxM1: nonqueued-sender-com-spec{data-element=Value, init-value=0}, provided-interface=VeOSMR_n_InputSpdMaxM1
      VeOSMR_n_InputSpdMinM2: nonqueued-sender-com-spec{data-element=Value, init-value=0}, provided-interface=VeOSMR_n_InputSpdMinM2
      VeOSMR_n_InputSpdMaxM2: nonqueued-sender-com-spec{data-element=Value, init-value=0}, provided-interface=VeOSMR_n_InputSpdMaxM2
      VeOSMR_e_HRSR_State: nonqueued-sender-com-spec{data-element=Value, init-value=CeOSMR_e_N_State}, provided-interface=VeOSMR_e_HRSR_State
      VeOSMR_b_LwrdCreepEna: nonqueued-sender-com-spec{data-element=Value, init-value=0}, provided-interface=VeOSMR_b_LwrdCreepEna
      VeOSMR_n_LwrdCreepIdleSpd: nonqueued-sender-com-spec{data-element=Value, init-value=0}, provided-interface=VeOSMR_n_LwrdCreepIdleSpd
      VeOSMR_n_TransMinEngSpd_xNiColdMin: nonqueued-sender-com-spec{data-element=Value, init-value=0}, provided-interface=VeOSMR_n_TransMinEngSpd_xNiColdMin
      VeOSMR_b_DisableLaunch: nonqueued-sender-com-spec{data-element=Value, init-value=0}, provided-interface=VeOSMR_b_DisableLaunch
      VeOSMR_b_MaxGearOffsetActv: nonqueued-sender-com-spec{data-element=Value, init-value=0}, provided-interface=VeOSMR_b_MaxGearOffsetActv
      VeOSMR_M_OutTrqRsrvIdle: nonqueued-sender-com-spec{data-element=Value, init-value=0}, provided-interface=VeOSMR_M_OutTrqRsrvIdle
      VeOSMR_e_SteadyTransSt: nonqueued-sender-com-spec{data-element=Value, init-value=CeOSMR_e_TransSt_Drive}, provided-interface=VeOSMR_e_SteadyTransSt
      VeOSMR_b_EngRevLim_Actv: nonqueued-sender-com-spec{data-element=Value, init-value=0}, provided-interface=VeOSMR_b_EngRevLim_Actv
      VeOSMR_b_TCaseN4HiShft_Actv: nonqueued-sender-com-spec{data-element=Value, init-value=0}, provided-interface=VeOSMR_b_TCaseN4HiShft_Actv
      VeOSMR_b_TcaseShftEffrtRdctn_Actv: nonqueued-sender-com-spec{data-element=Value, init-value=0}, provided-interface=VeOSMR_b_TcaseShftEffrtRdctn_Actv
      VeOSMR_b_ServEngOffReq_Actv: nonqueued-sender-com-spec{data-element=Value, init-value=0}, provided-interface=VeOSMR_b_ServEngOffReq_Actv
      VeOSMR_d_FnctnEnblReg: nonqueued-sender-com-spec{data-element=Value, init-value=0}, provided-interface=VeOSMR_d_FnctnEnblReg
      VeOSMR_M_TgtTrq_Min: nonqueued-sender-com-spec{data-element=Value, init-value=0}, provided-interface=VeOSMR_M_TgtTrq_Min
      VaOSMR_d_HardAllwdRaw: nonqueued-sender-com-spec{data-element=Value, init-value=6 x 0}, provided-interface=VaOSMR_d_HardAllwdRaw
      VaOSMR_i_IndexAllowed_MBNR: nonqueued-sender-com-spec{data-element=Value, init-value=9 x 0}, provided-interface=VaOSMR_i_IndexAllowed_MBNR
      VeOSMR_Cnt_IdxLength_MBNR: nonqueued-sender-com-spec{data-element=Value, init-value=0}, provided-interface=VeOSMR_Cnt_IdxLength_MBNR
      VaOSMR_n_InputSpdMinMBNR: nonqueued-sender-com-spec{data-element=Value, init-value=9 x 0}, provided-interface=VaOSMR_n_InputSpdMinMBNR
      VaOSMR_n_InputSpdMaxMBNR: nonqueued-sender-com-spec{data-element=Value, init-value=9 x 0}, provided-interface=VaOSMR_n_InputSpdMaxMBNR
      VaOSMR_i_MaxGrPerRngSt: nonqueued-sender-com-spec{data-element=Value, init-value=6 x 0}, provided-interface=VaOSMR_i_MaxGrPerRngSt
      VaOSMR_i_MinGrPerRngSt: nonqueued-sender-com-spec{data-element=Value, init-value=6 x 0}, provided-interface=VaOSMR_i_MinGrPerRngSt
      VeOSMR_b_NVHLimitation_Enbld: nonqueued-sender-com-spec{data-element=Value, init-value=0}, provided-interface=VeOSMR_b_NVHLimitation_Enbld
      VeOSMR_n_NiMax_NVH: nonqueued-sender-com-spec{data-element=Value, init-value=0}, provided-interface=VeOSMR_n_NiMax_NVH
      VeOSMR_b_PnLimitActvFlg: nonqueued-sender-com-spec{data-element=Value, init-value=0}, provided-interface=VeOSMR_b_PnLimitActvFlg
      VeOSMR_b_WEDclsdAllwdOpt: nonqueued-sender-com-spec{data-element=Value, init-value=0}, provided-interface=VeOSMR_b_WEDclsdAllwdOpt
      VaOSMR_P_PShiftMinLim: nonqueued-sender-com-spec{data-element=Value, init-value=[0, 0]}, provided-interface=VaOSMR_P_PShiftMinLim
      VaOSMR_P_PShiftMaxLim: nonqueued-sender-com-spec{data-element=Value, init-value=[0, 0]}, provided-interface=VaOSMR_P_PShiftMaxLim
      VeOSMR_M_OutTrqReqNetArb: nonqueued-sender-com-spec{data-element=Value, init-value=0}, provided-interface=VeOSMR_M_OutTrqReqNetArb
      VeOSMR_P_PoMaxLinConstrn: nonqueued-sender-com-spec{data-element=Value, init-value=0}, provided-interface=VeOSMR_P_PoMaxLinConstrn
      VeOSMR_i_DrvPrg_AutoRevMaxType: nonqueued-sender-com-spec{data-element=Value, init-value=0}, provided-interface=VeOSMR_i_DrvPrg_AutoRevMaxType
      VeOSMR_n_TransOutSpdSqncd: nonqueued-sender-com-spec{data-element=Value, init-value=0}, provided-interface=VeOSMR_n_TransOutSpdSqncd
      VeOSMR_n_TransOutSpdRawSqncd: nonqueued-sender-com-spec{data-element=Value, init-value=0}, provided-interface=VeOSMR_n_TransOutSpdRawSqncd
      VeOSMR_M_OutTrqReqNet: nonqueued-sender-com-spec{data-element=Value, init-value=0}, provided-interface=VeOSMR_M_OutTrqReqNet
      VaOSMR_n_EngCapability: nonqueued-sender-com-spec{data-element=Value, init-value=16 x 0}, provided-interface=VaOSMR_n_EngCapability
      VaOSMR_M_EngCapabilityMinOff: nonqueued-sender-com-spec{data-element=Value, init-value=16 x 0}, provided-interface=VaOSMR_M_EngCapabilityMinOff
      VaOSMR_M_EngCapabilityMaxLmtd: nonqueued-sender-com-spec{data-element=Value, init-value=16 x 0}, provided-interface=VaOSMR_M_EngCapabilityMaxLmtd
      VeOSMR_b_StgcNot_In_Transition: nonqueued-sender-com-spec{data-element=Value, init-value=0}, provided-interface=VeOSMR_b_StgcNot_In_Transition
      VeOSMR_e_Current_RngSt: nonqueued-sender-com-spec{data-element=Value, init-value=CeSCOR_e_SG_Neutral}, provided-interface=VeOSMR_e_Current_RngSt
      VeOSMR_e_CurrentGear: nonqueued-sender-com-spec{data-element=Value, init-value=CeTRNR_e_Neutral}, provided-interface=VeOSMR_e_CurrentGear
      VeOSMR_e_PrevDsrd_RngSt: nonqueued-sender-com-spec{data-element=Value, init-value=CeSCOR_e_SG_Neutral}, provided-interface=VeOSMR_e_PrevDsrd_RngSt
      VeOSMR_e_DesiredGear: nonqueued-sender-com-spec{data-element=Value, init-value=CeOHSR_e_SG_Reverse}, provided-interface=VeOSMR_e_DesiredGear
      VeOSMR_M_OutTrqReqArb_MA: nonqueued-sender-com-spec{data-element=Value, init-value=0}, provided-interface=VeOSMR_M_OutTrqReqArb_MA
      VeOSMR_M_OutTrqReqArb_MB: nonqueued-sender-com-spec{data-element=Value, init-value=0}, provided-interface=VeOSMR_M_OutTrqReqArb_MB
      VeOSMR_M_OutTrqReqArb_N: nonqueued-sender-com-spec{data-element=Value, init-value=0}, provided-interface=VeOSMR_M_OutTrqReqArb_N
      VeOSMR_M_ToFront4x4_Max: nonqueued-sender-com-spec{data-element=Value, init-value=0}, provided-interface=VeOSMR_M_ToFront4x4_Max
      VeOSMR_M_ToFront4x4_Min: nonqueued-sender-com-spec{data-element=Value, init-value=0}, provided-interface=VeOSMR_M_ToFront4x4_Min
      VeOSMR_M_ToRear4x4_Max: nonqueued-sender-com-spec{data-element=Value, init-value=0}, provided-interface=VeOSMR_M_ToRear4x4_Max
      VeOSMR_M_ToRear4x4_Min: nonqueued-sender-com-spec{data-element=Value, init-value=0}, provided-interface=VeOSMR_M_ToRear4x4_Min
      VeOSMR_M_OutTrqReqNetArbSqncd: nonqueued-sender-com-spec{data-element=Value, init-value=0}, provided-interface=VeOSMR_M_OutTrqReqNetArbSqncd
      VeOSMR_M_OutTrqReqArb_MBNR: nonqueued-sender-com-spec{data-element=Value, init-value=0}, provided-interface=VeOSMR_M_OutTrqReqArb_MBNR
      VeOSMR_r_CostFactSOCNeg_Stgc: nonqueued-sender-com-spec{data-element=Value, init-value=0}, provided-interface=VeOSMR_r_CostFactSOCNeg_Stgc
      VeOSMR_r_CostFactSOCPos_Stgc: nonqueued-sender-com-spec{data-element=Value, init-value=0}, provided-interface=VeOSMR_r_CostFactSOCPos_Stgc
      VeOSMR_P_BattPwrShift_Stgc: nonqueued-sender-com-spec{data-element=Value, init-value=0}, provided-interface=VeOSMR_P_BattPwrShift_Stgc
      VeOSMR_b_1DOptEnbl: nonqueued-sender-com-spec{data-element=Value, init-value=0}, provided-interface=VeOSMR_b_1DOptEnbl
      VeOSMR_n_Ni_ColdCtrl: nonqueued-sender-com-spec{data-element=Value, init-value=0}, provided-interface=VeOSMR_n_Ni_ColdCtrl
      VeOSMR_M_Ti_ColdCtrl_Stgc: nonqueued-sender-com-spec{data-element=Value, init-value=0}, provided-interface=VeOSMR_M_Ti_ColdCtrl_Stgc
      VeOSMR_r_ColdCtrlCostFact_Stgc: nonqueued-sender-com-spec{data-element=Value, init-value=0}, provided-interface=VeOSMR_r_ColdCtrlCostFact_Stgc
      VeOSMR_n_NiMinIdlNoFlyZone: nonqueued-sender-com-spec{data-element=Value, init-value=0}, provided-interface=VeOSMR_n_NiMinIdlNoFlyZone
      VeOSMR_n_NiMaxIdlNoFlyZone: nonqueued-sender-com-spec{data-element=Value, init-value=0}, provided-interface=VeOSMR_n_NiMaxIdlNoFlyZone
      VeOSMR_P_DrvrPdlCostOffsetNeg: nonqueued-sender-com-spec{data-element=Value, init-value=0}, provided-interface=VeOSMR_P_DrvrPdlCostOffsetNeg
      VeOSMR_r_DrvrPdlCostGainNeg: nonqueued-sender-com-spec{data-element=Value, init-value=0}, provided-interface=VeOSMR_r_DrvrPdlCostGainNeg
      VeOSMR_P_DrvrPdlCostOffsetPos: nonqueued-sender-com-spec{data-element=Value, init-value=0}, provided-interface=VeOSMR_P_DrvrPdlCostOffsetPos
      VeOSMR_r_DrvrPdlCostGainPos: nonqueued-sender-com-spec{data-element=Value, init-value=0}, provided-interface=VeOSMR_r_DrvrPdlCostGainPos
      VeOSMR_b_StgcRIPEnblOutTorqAccel: nonqueued-sender-com-spec{data-element=Value, init-value=0}, provided-interface=VeOSMR_b_StgcRIPEnblOutTorqAccel
      VeOSMR_b_StgcRIPEnblOutTorqNet: nonqueued-sender-com-spec{data-element=Value, init-value=0}, provided-interface=VeOSMR_b_StgcRIPEnblOutTorqNet
      VeOSMR_r_StgcRIPratioOutTorqAccel: nonqueued-sender-com-spec{data-element=Value, init-value=0}, provided-interface=VeOSMR_r_StgcRIPratioOutTorqAccel
      VeOSMR_r_StgcRIPratioOutTorqNet: nonqueued-sender-com-spec{data-element=Value, init-value=0}, provided-interface=VeOSMR_r_StgcRIPratioOutTorqNet
      VaOSMR_M_ToFToRLimOL: nonqueued-sender-com-spec{data-element=Value, init-value=[0, 0, 0, 0]}, provided-interface=VaOSMR_M_ToFToRLimOL
      VaOSMR_k_MeshLoss2ndOrderCoeff: nonqueued-sender-com-spec{data-element=Value, init-value=9 x 0}, provided-interface=VaOSMR_k_MeshLoss2ndOrderCoeff
      VaOSMR_k_MeshLoss1stOrderCoeff: nonqueued-sender-com-spec{data-element=Value, init-value=9 x 0}, provided-interface=VaOSMR_k_MeshLoss1stOrderCoeff
      VaOSMR_k_MeshLoss0thOrderCoeff: nonqueued-sender-com-spec{data-element=Value, init-value=9 x 0}, provided-interface=VaOSMR_k_MeshLoss0thOrderCoeff
      VaOSMR_k_MeshLoss2ndOrderCoeffEV: nonqueued-sender-com-spec{data-element=Value, init-value=9 x 0}, provided-interface=VaOSMR_k_MeshLoss2ndOrderCoeffEV
      VaOSMR_k_MeshLoss1stOrderCoeffEV: nonqueued-sender-com-spec{data-element=Value, init-value=9 x 0}, provided-interface=VaOSMR_k_MeshLoss1stOrderCoeffEV
      VaOSMR_k_MeshLoss0thOrderCoeffEV: nonqueued-sender-com-spec{data-element=Value, init-value=9 x 0}, provided-interface=VaOSMR_k_MeshLoss0thOrderCoeffEV
      VeOSMR_P_PwrRsrv4EngmtRaw: nonqueued-sender-com-spec{data-element=Value, init-value=0}, provided-interface=VeOSMR_P_PwrRsrv4EngmtRaw
      VeOSMR_M_BeltCapMaxPrll: nonqueued-sender-com-spec{data-element=Value, init-value=0}, provided-interface=VeOSMR_M_BeltCapMaxPrll
      VeOSMR_M_BeltCapMinPrll: nonqueued-sender-com-spec{data-element=Value, init-value=0}, provided-interface=VeOSMR_M_BeltCapMinPrll
      VeOSMR_M_BeltCapMaxSer_Eff: nonqueued-sender-com-spec{data-element=Value, init-value=0}, provided-interface=VeOSMR_M_BeltCapMaxSer_Eff
      VeOSMR_M_BeltCapMinSer_Eff: nonqueued-sender-com-spec{data-element=Value, init-value=0}, provided-interface=VeOSMR_M_BeltCapMinSer_Eff
      VeOSMR_r_MachAPwrLossCostFactor: nonqueued-sender-com-spec{data-element=Value, init-value=0}, provided-interface=VeOSMR_r_MachAPwrLossCostFactor
      VeOSMR_r_MachBPwrLossCostFactor: nonqueued-sender-com-spec{data-element=Value, init-value=0}, provided-interface=VeOSMR_r_MachBPwrLossCostFactor
      VeOSMR_r_MachCPwrLossCostFactor: nonqueued-sender-com-spec{data-element=Value, init-value=0}, provided-interface=VeOSMR_r_MachCPwrLossCostFactor
      VeOSMR_r_BattPwrLossCostFactor: nonqueued-sender-com-spec{data-element=Value, init-value=0}, provided-interface=VeOSMR_r_BattPwrLossCostFactor
